# netx90_app register map
File version: 1.0
CPU: CM4 r0p1, little endian, MPU, FPU, 4 interrupt priority bits, 78 interrupts
Registers are 32-bit, read-write, reset 0x0 unless marked. A register's access mark holds for its fields unless they carry their own. Offsets are from the block's base; [hi:lo] are bit positions; 'fields as' and 'values as' point back to an identical list.

## ecc_ctrl_app
Base 0xFF801800
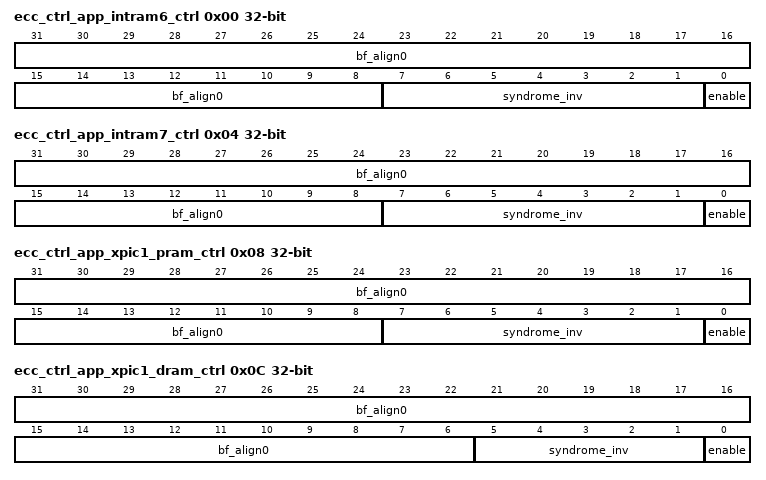
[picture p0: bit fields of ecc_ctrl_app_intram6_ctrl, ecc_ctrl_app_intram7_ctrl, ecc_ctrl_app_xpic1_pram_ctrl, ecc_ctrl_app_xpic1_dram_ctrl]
0x00 ecc_ctrl_app_intram6_ctrl (reset mask 0xFF) — INTRAM6 syndrome manipulation register
  [31:8] bf_align0 — bitField alignment value for aeabi compatibility
  [7:1] syndrome_inv — Inverts syndrome bits for ECC testing
  [0] enable — enable ECC
0x04 ecc_ctrl_app_intram7_ctrl (reset mask 0xFF) — INTRAM7 syndrome manipulation register
  fields as ecc_ctrl_app_intram6_ctrl
0x08 ecc_ctrl_app_xpic1_pram_ctrl (reset mask 0xFF) — XPIC1_PRAM syndrome manipulation register
  fields as ecc_ctrl_app_intram6_ctrl
0x0C ecc_ctrl_app_xpic1_dram_ctrl (reset mask 0x3F) — XPIC1_DRAM syndrome manipulation register
  [31:6] bf_align0 — bitField alignment value for aeabi compatibility
  [5:1] syndrome_inv — Inverts syndrome bits for ECC testing
  [0] enable — enable ECC
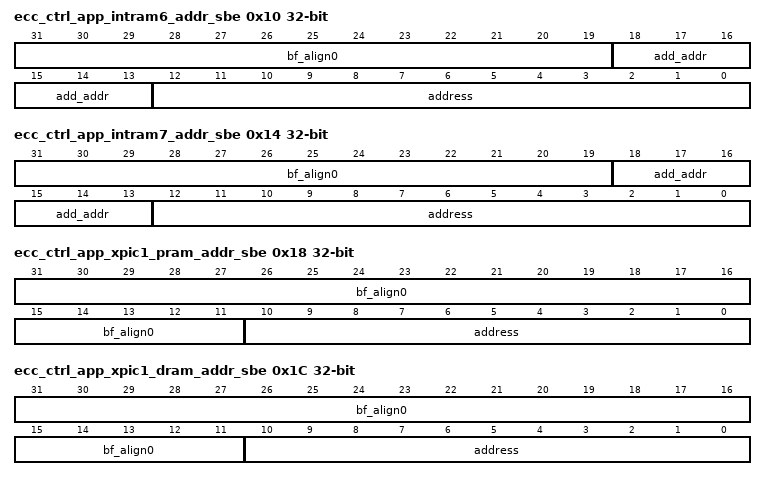
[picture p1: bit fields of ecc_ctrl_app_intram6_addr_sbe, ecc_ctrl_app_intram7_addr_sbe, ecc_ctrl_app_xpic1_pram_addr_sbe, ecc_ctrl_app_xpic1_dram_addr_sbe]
0x10 ecc_ctrl_app_intram6_addr_sbe ro (reset mask 0x7FFFF) — RAM Address of ECC single bit error (SBE): This register logs the RAM address where first ECC SBE occured. This first SBE address will be stored (even in case of further SBEs) until the appropriate bit in status_sbe register was cleared. Note1: Not all RAM ECCs support error address logging, e.g. dual-port RAMs Note2: This is the real RAM address, i.e. a 32-bit address except at xMAC 64-bit RAMs or RAMs that are not directly accessible by CPU.
  [31:19] bf_align0 — bitField alignment value for aeabi compatibility
  [18:13] add_addr — RAM readmodwrite(1) and number of master that started errorneous RAM access(5)
  [12:0] address — Address of last ECC single bit error
0x14 ecc_ctrl_app_intram7_addr_sbe ro (reset mask 0x7FFFF) — RAM Address of ECC single bit error (SBE): This register logs the RAM address where first ECC SBE occured. This first SBE address will be stored (even in case of further SBEs) until the appropriate bit in status_sbe register was cleared. Note1: Not all RAM ECCs support error address logging, e.g. dual-port RAMs Note2: This is the real RAM address, i.e. a 32-bit address except at xMAC 64-bit RAMs or RAMs that are not directly accessible by CPU.
  fields as ecc_ctrl_app_intram6_addr_sbe
0x18 ecc_ctrl_app_xpic1_pram_addr_sbe ro (reset mask 0x7FF) — RAM Address of ECC single bit error (SBE): This register logs the RAM address where first ECC SBE occured. This first SBE address will be stored (even in case of further SBEs) until the appropriate bit in status_sbe register was cleared. Note1: Not all RAM ECCs support error address logging, e.g. dual-port RAMs Note2: This is the real RAM address, i.e. a 32-bit address except at xMAC 64-bit RAMs or RAMs that are not directly accessible by CPU.
  [31:11] bf_align0 — bitField alignment value for aeabi compatibility
  [10:0] address — Address of last ECC single bit error
0x1C ecc_ctrl_app_xpic1_dram_addr_sbe ro (reset mask 0x7FF) — RAM Address of ECC single bit error (SBE): This register logs the RAM address where first ECC SBE occured. This first SBE address will be stored (even in case of further SBEs) until the appropriate bit in status_sbe register was cleared. Note1: Not all RAM ECCs support error address logging, e.g. dual-port RAMs Note2: This is the real RAM address, i.e. a 32-bit address except at xMAC 64-bit RAMs or RAMs that are not directly accessible by CPU.
  fields as ecc_ctrl_app_xpic1_pram_addr_sbe
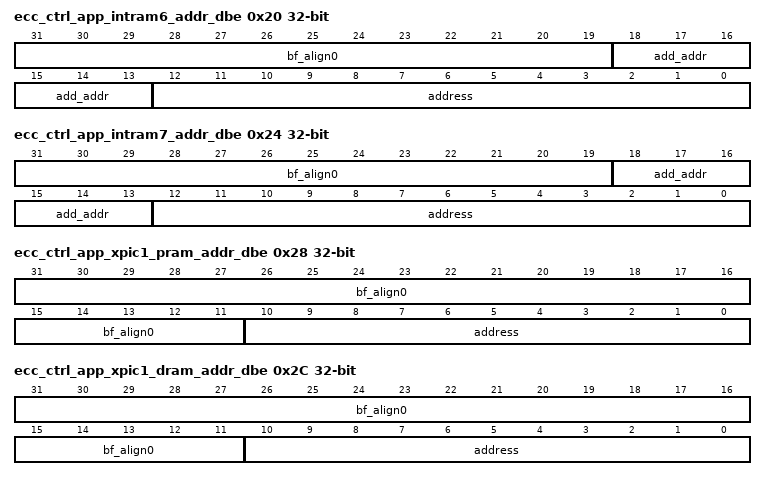
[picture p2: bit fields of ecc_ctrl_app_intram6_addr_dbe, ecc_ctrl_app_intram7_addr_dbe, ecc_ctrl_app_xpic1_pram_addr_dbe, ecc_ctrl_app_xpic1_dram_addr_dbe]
0x20 ecc_ctrl_app_intram6_addr_dbe ro (reset mask 0x7FFFF) — RAM Address of ECC single bit error (DBE): This register logs the RAM address where first ECC DBE occured. This first DBE address will be stored (even in case of further DBEs) until the appropriate bit in status_sbe register was cleared. Note1: Not all RAM ECCs support error address logging, e.g. dual-port RAMs Note2: This is the real RAM address, i.e. a 32-bit address except at xMAC 64-bit RAMs or RAMs that are not directly accessible by CPU.
  [31:19] bf_align0 — bitField alignment value for aeabi compatibility
  [18:13] add_addr — RAM readmodwrite(1) and number of master that started errorneous RAM access(5)
  [12:0] address — Address of last ECC double bit error
0x24 ecc_ctrl_app_intram7_addr_dbe ro (reset mask 0x7FFFF) — RAM Address of ECC single bit error (DBE): This register logs the RAM address where first ECC DBE occured. This first DBE address will be stored (even in case of further DBEs) until the appropriate bit in status_sbe register was cleared. Note1: Not all RAM ECCs support error address logging, e.g. dual-port RAMs Note2: This is the real RAM address, i.e. a 32-bit address except at xMAC 64-bit RAMs or RAMs that are not directly accessible by CPU.
  fields as ecc_ctrl_app_intram6_addr_dbe
0x28 ecc_ctrl_app_xpic1_pram_addr_dbe ro (reset mask 0x7FF) — RAM Address of ECC single bit error (DBE): This register logs the RAM address where first ECC DBE occured. This first DBE address will be stored (even in case of further DBEs) until the appropriate bit in status_sbe register was cleared. Note1: Not all RAM ECCs support error address logging, e.g. dual-port RAMs Note2: This is the real RAM address, i.e. a 32-bit address except at xMAC 64-bit RAMs or RAMs that are not directly accessible by CPU.
  [31:11] bf_align0 — bitField alignment value for aeabi compatibility
  [10:0] address — Address of last ECC double bit error
0x2C ecc_ctrl_app_xpic1_dram_addr_dbe ro (reset mask 0x7FF) — RAM Address of ECC single bit error (DBE): This register logs the RAM address where first ECC DBE occured. This first DBE address will be stored (even in case of further DBEs) until the appropriate bit in status_sbe register was cleared. Note1: Not all RAM ECCs support error address logging, e.g. dual-port RAMs Note2: This is the real RAM address, i.e. a 32-bit address except at xMAC 64-bit RAMs or RAMs that are not directly accessible by CPU.
  fields as ecc_ctrl_app_xpic1_pram_addr_dbe
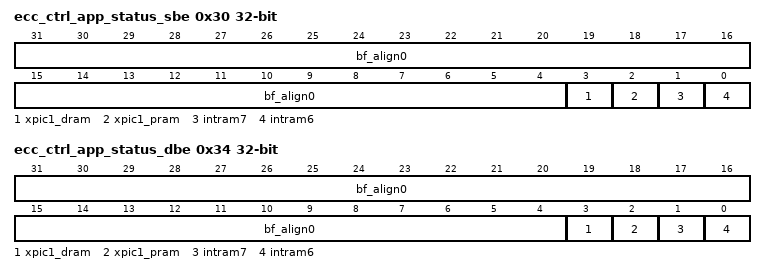
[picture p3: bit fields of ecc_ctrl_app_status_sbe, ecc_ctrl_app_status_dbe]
0x30 ecc_ctrl_app_status_sbe (reset mask 0xF) — ECC status SBE: This register collects single bit error (SBE) status information. In case of ECC SBE, a bit in this register will be set. Bits can be reset by writing '1' to the apprpriate bit position (write to clear). If a SBE or DBE bit is set, IRQ signal will be asserted. Note: No mask register is required, as error correction can be enabled for each RAM separately.
  [31:4] bf_align0 — bitField alignment value for aeabi compatibility
  [3] xpic1_dram — XPIC1_DRAM Single Bit Error occured
  [2] xpic1_pram — XPIC1_PRAM Single Bit Error occured
  [1] intram7 — INTRAM7 Single Bit Error occured
  [0] intram6 — INTRAM6 Single Bit Error occured
0x34 ecc_ctrl_app_status_dbe (reset mask 0xF) — ECC status DBE: This register collects double bit error (DBE) status information. In case of ECC DBE, a bit of the appropriate RAM in this register will be set. Bits can be reset by writing '1' to the apprpriate bit position (write to clear). If a SBE or DBE bit is set, IRQ signal will be asserted. Note: No mask register is required, as error correction can be enabled for each RAM separately.
  [31:4] bf_align0 — bitField alignment value for aeabi compatibility
  [3] xpic1_dram — XPIC1_DRAM Double Bit Error occured
  [2] xpic1_pram — XPIC1_PRAM Double Bit Error occured
  [1] intram7 — INTRAM7 Double Bit Error occured
  [0] intram6 — INTRAM6 Double Bit Error occured
